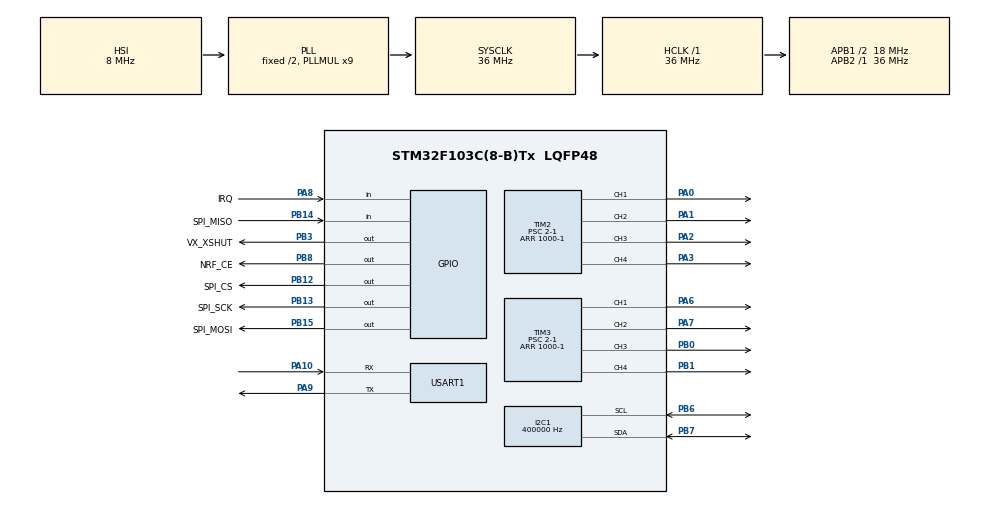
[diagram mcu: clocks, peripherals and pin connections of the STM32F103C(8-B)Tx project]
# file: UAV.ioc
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I2C1.ClockSpeed=400000
I2C1.I2C_Mode=I2C_Fast
Mcu.Family=STM32F1
Mcu.Name=STM32F103C(8-B)Tx
Mcu.Package=LQFP48
NVIC.PriorityGroup=NVIC_PRIORITYGROUP_4
PA0-WKUP.Signal=S_TIM2_CH1_ETR
PA1.Signal=S_TIM2_CH2
PA10.Mode=Asynchronous
PA10.Signal=USART1_RX
PA13.Mode=Serial_Wire
PA13.Signal=SYS_JTMS-SWDIO
PA14.Mode=Serial_Wire
PA14.Signal=SYS_JTCK-SWCLK
PA2.Signal=S_TIM2_CH3
PA3.Signal=S_TIM2_CH4
PA6.Signal=S_TIM3_CH1
PA7.Signal=S_TIM3_CH2
PA8.GPIO_Label=IRQ
PA8.GPIO_PuPd=GPIO_PULLUP
PA8.Signal=GPIO_Input
PA9.Mode=Asynchronous
PA9.Signal=USART1_TX
PB0.Signal=S_TIM3_CH3
PB1.Signal=S_TIM3_CH4
PB12.GPIO_Label=SPI_CS
PB12.PinState=GPIO_PIN_SET
PB12.Signal=GPIO_Output
PB13.GPIO_Label=SPI_SCK
PB13.PinState=GPIO_PIN_RESET
PB13.Signal=GPIO_Output
PB14.GPIO_Label=SPI_MISO
PB14.Signal=GPIO_Input
PB15.GPIO_Label=SPI_MOSI
PB15.PinState=GPIO_PIN_SET
PB15.Signal=GPIO_Output
PB3.GPIO_Label=VX_XSHUT
PB3.PinState=GPIO_PIN_SET
PB3.Signal=GPIO_Output
PB6.Mode=I2C
PB6.Signal=I2C1_SCL
PB7.Mode=I2C
PB7.Signal=I2C1_SDA
PB8.GPIO_Label=NRF_CE
PB8.Signal=GPIO_Output
ProjectManager.HeapSize=0x200
ProjectManager.StackSize=0x400
ProjectManager.TargetToolchain=MDK-ARM V5.32
RCC.AHBFreq_Value=36000000
RCC.APB1CLKDivider=RCC_HCLK_DIV2
RCC.APB1Freq_Value=18000000
RCC.APB1TimFreq_Value=36000000
RCC.APB2Freq_Value=36000000
RCC.APB2TimFreq_Value=36000000
RCC.HCLKFreq_Value=36000000
RCC.PLLMUL=RCC_PLL_MUL9
RCC.SYSCLKFreq_VALUE=36000000
RCC.SYSCLKSource=RCC_SYSCLKSOURCE_PLLCLK
RCC.USBFreq_Value=36000000
SH.S_TIM2_CH1_ETR.0=TIM2_CH1,PWM Generation1 CH1
SH.S_TIM2_CH2.0=TIM2_CH2,PWM Generation2 CH2
SH.S_TIM2_CH3.0=TIM2_CH3,PWM Generation3 CH3
SH.S_TIM2_CH4.0=TIM2_CH4,PWM Generation4 CH4
SH.S_TIM3_CH1.0=TIM3_CH1,PWM Generation1 CH1
SH.S_TIM3_CH2.0=TIM3_CH2,PWM Generation2 CH2
SH.S_TIM3_CH3.0=TIM3_CH3,PWM Generation3 CH3
SH.S_TIM3_CH4.0=TIM3_CH4,PWM Generation4 CH4
TIM2.Channel-PWM\ Generation1\ CH1=TIM_CHANNEL_1
TIM2.Channel-PWM\ Generation2\ CH2=TIM_CHANNEL_2
TIM2.Channel-PWM\ Generation3\ CH3=TIM_CHANNEL_3
TIM2.Channel-PWM\ Generation4\ CH4=TIM_CHANNEL_4
TIM2.Period=1000-1
TIM2.Prescaler=2-1
TIM2.Pulse-PWM\ Generation1\ CH1=0
TIM2.Pulse-PWM\ Generation2\ CH2=0
TIM2.Pulse-PWM\ Generation3\ CH3=0
TIM2.Pulse-PWM\ Generation4\ CH4=0
TIM3.Channel-PWM\ Generation1\ CH1=TIM_CHANNEL_1
TIM3.Channel-PWM\ Generation2\ CH2=TIM_CHANNEL_2
TIM3.Channel-PWM\ Generation3\ CH3=TIM_CHANNEL_3
TIM3.Channel-PWM\ Generation4\ CH4=TIM_CHANNEL_4
TIM3.Period=1000-1
TIM3.Prescaler=2-1
TIM3.Pulse-PWM\ Generation1\ CH1=1000
TIM3.Pulse-PWM\ Generation2\ CH2=1000
TIM3.Pulse-PWM\ Generation3\ CH3=1000
TIM3.Pulse-PWM\ Generation4\ CH4=1000
USART1.VirtualMode=VM_ASYNC
VP_TIM2_VS_ClockSourceINT.Mode=Internal
VP_TIM3_VS_ClockSourceINT.Mode=Internal
board=custom

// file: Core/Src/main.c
/* USER CODE BEGIN Header */
/**
  ******************************************************************************
  * @file           : main.c
  * @brief          : Main program body
  ******************************************************************************
  * @attention
  *
  * Copyright (c) 2026 STMicroelectronics.
  * All rights reserved.
  *
  * This software is licensed under terms that can be found in the LICENSE file
  * in the root directory of this software component.
  * If no LICENSE file comes with this software, it is provided AS-IS.
  *
  ******************************************************************************
  */
/* USER CODE END Header */
#include "main.h"
#include "i2c.h"
#include "tim.h"
#include "usart.h"
#include "gpio.h"

/* USER CODE BEGIN Includes */
#include "Com_debug.h"
#include "NRF24L01.h"
#include "FreeRTOS_Task.h"
/* USER CODE END Includes */

void SystemClock_Config(void);

int main(void)
{

  /* MCU Configuration--------------------------------------------------------*/

  /* Reset of all peripherals, Initializes the Flash interface and the Systick. */
  HAL_Init();

  /* Configure the system clock */
  SystemClock_Config();

  /* Initialize all configured peripherals */
  MX_GPIO_Init();
  MX_TIM2_Init();
  MX_USART1_UART_Init();
  MX_TIM3_Init();
  MX_I2C1_Init();
  /* USER CODE BEGIN 2 */

  debug_printf("Hello UAV\r\n");
  NRF24L01_Init();
  FreeRTOS_Start();
  /* USER CODE END 2 */

  /* Infinite loop */
  while (1)
  {

  }
}

void SystemClock_Config(void)
{
  RCC_OscInitTypeDef RCC_OscInitStruct = {0};
  RCC_ClkInitTypeDef RCC_ClkInitStruct = {0};

  /** Initializes the RCC Oscillators according to the specified parameters
  * in the RCC_OscInitTypeDef structure.
  */
  RCC_OscInitStruct.OscillatorType = RCC_OSCILLATORTYPE_HSI;
  RCC_OscInitStruct.HSIState = RCC_HSI_ON;
  RCC_OscInitStruct.HSICalibrationValue = RCC_HSICALIBRATION_DEFAULT;
  RCC_OscInitStruct.PLL.PLLState = RCC_PLL_ON;
  RCC_OscInitStruct.PLL.PLLSource = RCC_PLLSOURCE_HSI_DIV2;
  RCC_OscInitStruct.PLL.PLLMUL = RCC_PLL_MUL9;
  if (HAL_RCC_OscConfig(&RCC_OscInitStruct) != HAL_OK)
  {
    Error_Handler();
  }

  /** Initializes the CPU, AHB and APB buses clocks
  */
  RCC_ClkInitStruct.ClockType = RCC_CLOCKTYPE_HCLK|RCC_CLOCKTYPE_SYSCLK
                              |RCC_CLOCKTYPE_PCLK1|RCC_CLOCKTYPE_PCLK2;
  RCC_ClkInitStruct.SYSCLKSource = RCC_SYSCLKSOURCE_PLLCLK;
  RCC_ClkInitStruct.AHBCLKDivider = RCC_SYSCLK_DIV1;
  RCC_ClkInitStruct.APB1CLKDivider = RCC_HCLK_DIV2;
  RCC_ClkInitStruct.APB2CLKDivider = RCC_HCLK_DIV1;

  if (HAL_RCC_ClockConfig(&RCC_ClkInitStruct, FLASH_LATENCY_1) != HAL_OK)
  {
    Error_Handler();
  }
}

void Error_Handler(void)
{
  __disable_irq();
  while (1)
  {
  }
}
